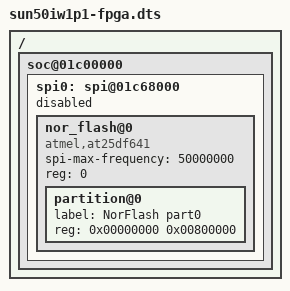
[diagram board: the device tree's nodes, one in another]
/*
 * Allwinner Technology CO., Ltd. sun50iw1p1 fpga board.
 *
 * fpga board support.
 */

/dts-v1/;
#include "sun50iw1p1.dtsi"

/{

	soc@01c00000 {
		spi0: spi@01c68000 {
			status = "disabled";

			nor_flash@0 {
				#address-cells = <1>;
				#size-cells = <1>;
				compatible = "atmel,at25df641";
				spi-max-frequency = <50000000>;
				reg = <0>;	/* Chip select 0 */

				partition@0 {
					label = "NorFlash part0";
					reg = <0x00000000 0x00800000>;
				};
			};
		};
	};
};
